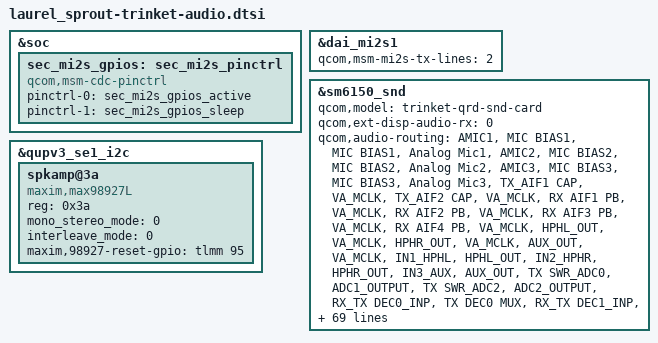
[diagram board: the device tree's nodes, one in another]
&soc {
	/delete-node/ dai_sen_auxpcm;
	/delete-node/ tdm_sen_rx;

	sec_mi2s_gpios: sec_mi2s_pinctrl {
		compatible = "qcom,msm-cdc-pinctrl";
		pinctrl-names = "aud_active", "aud_sleep";
		pinctrl-0 = <&sec_mi2s_gpios_active>;
		pinctrl-1 = <&sec_mi2s_gpios_sleep>;
	};
};

&dai_mi2s1 {
	qcom,msm-mi2s-tx-lines = <2>;
};

&sm6150_snd {
	status = "okay";
	qcom,model = "trinket-qrd-snd-card";
	qcom,ext-disp-audio-rx = <0>;
	qcom,audio-routing =
		"AMIC1", "MIC BIAS1",
		"MIC BIAS1", "Analog Mic1",
		"AMIC2", "MIC BIAS2",
		"MIC BIAS2", "Analog Mic2",
		"AMIC3", "MIC BIAS3",
		"MIC BIAS3", "Analog Mic3",
		"TX_AIF1 CAP", "VA_MCLK",
		"TX_AIF2 CAP", "VA_MCLK",
		"RX AIF1 PB", "VA_MCLK",
		"RX AIF2 PB", "VA_MCLK",
		"RX AIF3 PB", "VA_MCLK",
		"RX AIF4 PB", "VA_MCLK",
		"HPHL_OUT", "VA_MCLK",
		"HPHR_OUT", "VA_MCLK",
		"AUX_OUT", "VA_MCLK",
		"IN1_HPHL", "HPHL_OUT",
		"IN2_HPHR", "HPHR_OUT",
		"IN3_AUX", "AUX_OUT",
		"TX SWR_ADC0", "ADC1_OUTPUT",
		"TX SWR_ADC2", "ADC2_OUTPUT",
		"RX_TX DEC0_INP", "TX DEC0 MUX",
		"RX_TX DEC1_INP", "TX DEC1 MUX",
		"RX_TX DEC2_INP", "TX DEC2 MUX",
		"RX_TX DEC3_INP", "TX DEC3 MUX";
		qcom,msm-mbhc-gnd-swh = <0>;
		qcom,wsa-max-devs = <0>;

		/delete-property/ qcom,mbhc-audio-jack-type;

		/delete-property/ qcom,wsa-devs;
		/delete-property/ qcom,wsa-aux-dev-prefix;

		/delete-property/ qcom,mbhc-audio-jack-type;
		fsa4480-i2c-handle;
		qcom,sec-mi2s-gpios = <&sec_mi2s_gpios>;
};

&sm6150_snd {
	asoc-cpu =<&dai_mi2s0>, <&dai_mi2s1>,
			<&dai_mi2s2>, <&dai_mi2s3>,
			<&dai_mi2s4>, <&dai_pri_auxpcm>,
			<&dai_sec_auxpcm>, <&dai_tert_auxpcm>,
			<&dai_quat_auxpcm>, <&dai_quin_auxpcm>,
			<&afe_pcm_rx>, <&afe_pcm_tx>, <&afe_proxy_rx>,
			<&afe_proxy_tx>, <&incall_record_rx>,
			<&incall_record_tx>, <&incall_music_rx>,
			<&incall_music_2_rx>,
			<&sb_7_rx>, <&sb_7_tx>, <&sb_8_tx>, <&sb_8_rx>,
			<&proxy_rx>, <&proxy_tx>,
			<&usb_audio_rx>, <&usb_audio_tx>,
			<&dai_pri_tdm_rx_0>, <&dai_pri_tdm_tx_0>,
			<&dai_sec_tdm_rx_0>, <&dai_sec_tdm_tx_0>,
			<&dai_tert_tdm_rx_0>, <&dai_tert_tdm_tx_0>,
			<&dai_quat_tdm_rx_0>, <&dai_quat_tdm_tx_0>,
			<&dai_quin_tdm_rx_0>, <&dai_quin_tdm_tx_0>,
			<&wsa_cdc_dma_0_rx>, <&wsa_cdc_dma_0_tx>,
			<&wsa_cdc_dma_1_rx>, <&wsa_cdc_dma_1_tx>,
			<&wsa_cdc_dma_2_tx>,
			<&rx_cdc_dma_0_rx>, <&tx_cdc_dma_0_tx>,
			<&rx_cdc_dma_1_rx>, <&tx_cdc_dma_1_tx>,
			<&rx_cdc_dma_2_rx>, <&tx_cdc_dma_2_tx>,
			<&rx_cdc_dma_3_rx>, <&tx_cdc_dma_3_tx>,
			<&rx_cdc_dma_4_rx>, <&tx_cdc_dma_4_tx>,
			<&rx_cdc_dma_5_rx>, <&tx_cdc_dma_5_tx>,
			<&rx_cdc_dma_6_rx>, <&rx_cdc_dma_7_rx>;
	asoc-cpu-names ="msm-dai-q6-mi2s.0", "msm-dai-q6-mi2s.1",
			"msm-dai-q6-mi2s.2", "msm-dai-q6-mi2s.3",
			"msm-dai-q6-mi2s.4", "msm-dai-q6-auxpcm.1",
			"msm-dai-q6-auxpcm.2", "msm-dai-q6-auxpcm.3",
			"msm-dai-q6-auxpcm.4", "msm-dai-q6-auxpcm.5",
			"msm-dai-q6-dev.224",
			"msm-dai-q6-dev.225", "msm-dai-q6-dev.241",
			"msm-dai-q6-dev.240", "msm-dai-q6-dev.32771",
			"msm-dai-q6-dev.32772", "msm-dai-q6-dev.32773",
			"msm-dai-q6-dev.32770", "msm-dai-q6-dev.16398",
			"msm-dai-q6-dev.16399", "msm-dai-q6-dev.16401",
			"msm-dai-q6-dev.16400",
			"msm-dai-q6-dev.8194", "msm-dai-q6-dev.8195",
			"msm-dai-q6-dev.28672", "msm-dai-q6-dev.28673",
			"msm-dai-q6-tdm.36864", "msm-dai-q6-tdm.36865",
			"msm-dai-q6-tdm.36880", "msm-dai-q6-tdm.36881",
			"msm-dai-q6-tdm.36896", "msm-dai-q6-tdm.36897",
			"msm-dai-q6-tdm.36912", "msm-dai-q6-tdm.36913",
			"msm-dai-q6-tdm.36928", "msm-dai-q6-tdm.36929",
			"msm-dai-cdc-dma-dev.45056",
			"msm-dai-cdc-dma-dev.45057",
			"msm-dai-cdc-dma-dev.45058",
			"msm-dai-cdc-dma-dev.45059",
			"msm-dai-cdc-dma-dev.45061",
			"msm-dai-cdc-dma-dev.45104",
			"msm-dai-cdc-dma-dev.45105",
			"msm-dai-cdc-dma-dev.45106",
			"msm-dai-cdc-dma-dev.45107",
			"msm-dai-cdc-dma-dev.45108",
			"msm-dai-cdc-dma-dev.45109",
			"msm-dai-cdc-dma-dev.45110",
			"msm-dai-cdc-dma-dev.45111",
			"msm-dai-cdc-dma-dev.45112",
			"msm-dai-cdc-dma-dev.45113",
			"msm-dai-cdc-dma-dev.45114",
			"msm-dai-cdc-dma-dev.45115",
			"msm-dai-cdc-dma-dev.45116",
			"msm-dai-cdc-dma-dev.45118";
};


&qupv3_se1_i2c {
	status = "okay";
		spkamp@3a {/* max98927 smartpa device*/
		compatible = "maxim,max98927L";
		status = "okay";
		reg = <0x3a>;
		mono_stereo_mode = <0>;
		interleave_mode = <0>;
		maxim,98927-reset-gpio = <&tlmm 95 0>;
	};
};
